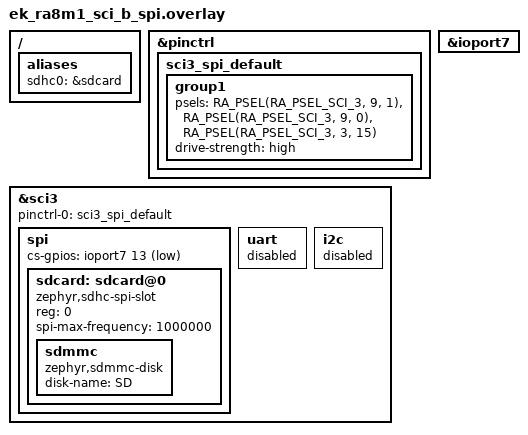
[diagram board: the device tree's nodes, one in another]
/*
 * Copyright (c) 2025 Renesas Electronics Corporation
 * SPDX-License-Identifier: Apache-2.0
 */

/ {
	aliases {
		sdhc0 = &sdcard;
	};
};

&pinctrl {
	sci3_spi_default: sci3_spi_default {
		group1 {
			/* MISO MOSI SCK */
			psels = <RA_PSEL(RA_PSEL_SCI_3, 9, 1)>,
				<RA_PSEL(RA_PSEL_SCI_3, 9, 0)>,
				<RA_PSEL(RA_PSEL_SCI_3, 3, 15)>;
			drive-strength = "high";
		};
	};
};

&ioport7 {
	status = "okay";
};

&sci3 {
	pinctrl-0 = <&sci3_spi_default>;
	pinctrl-names = "default";

	spi {
		cs-gpios = <&ioport7 13 GPIO_ACTIVE_LOW>;
		status = "okay";

		sdcard: sdcard@0 {
			compatible = "zephyr,sdhc-spi-slot";
			reg = <0>;
			status = "okay";
			spi-max-frequency = <1000000>;

			sdmmc {
				compatible = "zephyr,sdmmc-disk";
				disk-name = "SD";
				status = "okay";
			};
		};
	};

	uart {
		status = "disabled";
	};

	i2c {
		status = "disabled";
	};
};
